AUTOSAR XML (schema 00046)
package /ComponentTypes
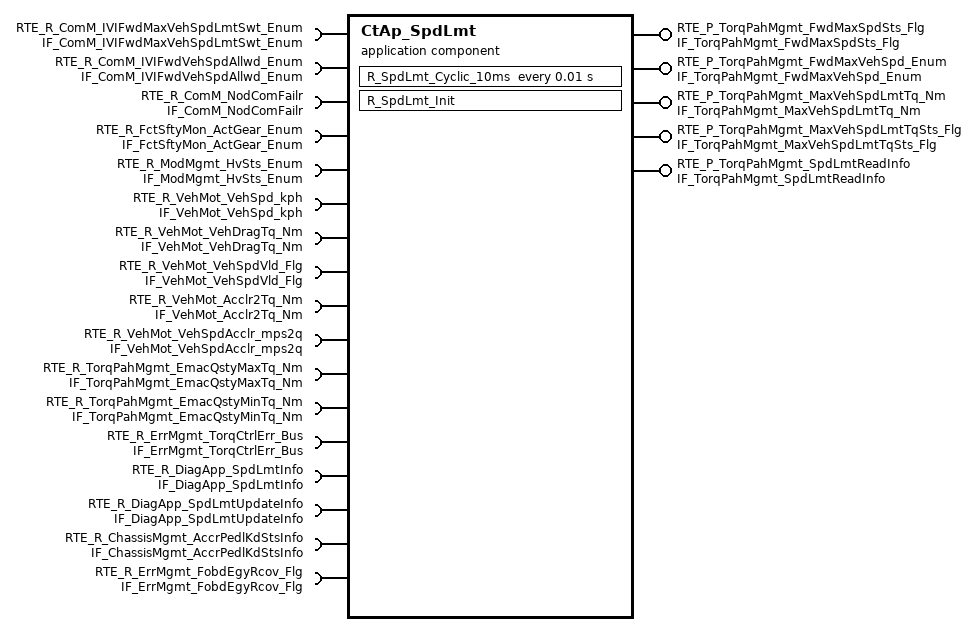
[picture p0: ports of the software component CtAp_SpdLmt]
  application sw component type CtAp_SpdLmt
    10 x require port:
      RTE_R_ComM_IVIFwdMaxVehSpdLmtSwt_Enum: nonqueued-receiver-com-spec{data-element=tec_ComM_IVIFwdMaxVehSpdLmtSwt_Enum, filter=data-filter-type=ALWAYS, init-value=0}, required-interface=IF_ComM_IVIFwdMaxVehSpdLmtSwt_Enum
      RTE_R_ComM_IVIFwdVehSpdAllwd_Enum: nonqueued-receiver-com-spec{data-element=tec_ComM_IVIFwdVehSpdAllwd_Enum, filter=data-filter-type=ALWAYS, init-value=0}, required-interface=IF_ComM_IVIFwdVehSpdAllwd_Enum
      RTE_R_ComM_NodComFailr: required-interface=IF_ComM_NodComFailr
        required-com-specs:
          data-element=tec_ComM_SGWNodComFailr_Flg, filter=data-filter-type=ALWAYS, init-value=0
          data-element=tec_ComM_CGWNodComFailr_Flg, filter=data-filter-type=ALWAYS, init-value=0
          data-element=tec_ComM_TCUNodComFailr_Flg, filter=data-filter-type=ALWAYS, init-value=0
          data-element=tec_ComM_BCMNodComFailr_Flg, filter=data-filter-type=ALWAYS, init-value=0
          data-element=tec_ComM_PRNDNodComFailr_Flg, filter=data-filter-type=ALWAYS, init-value=0
          data-element=tec_ComM_IVINodComFailr_Flg, filter=data-filter-type=ALWAYS, init-value=0
          data-element=tec_ComM_DCDCNodComFailr_Flg, filter=data-filter-type=ALWAYS, init-value=0
          data-element=tec_ComM_OBCNodComFailr_Flg, filter=data-filter-type=ALWAYS, init-value=0
          data-element=tec_ComM_CHIBSNodComFailr_Flg, filter=data-filter-type=ALWAYS, init-value=0
          data-element=tec_ComM_MCUNodComFailr_Flg, filter=data-filter-type=ALWAYS, init-value=0
          data-element=tec_ComM_EVCOMNodComFailr_Flg, filter=data-filter-type=ALWAYS, init-value=0
          data-element=tec_ComM_EPTIBSNodComFailr_Flg, filter=data-filter-type=ALWAYS, init-value=0
          data-element=tec_ComM_DCMNodComFailr_Flg, filter=data-filter-type=ALWAYS, init-value=0
          data-element=tec_ComM_BMSNodComFailr_Flg, filter=data-filter-type=ALWAYS, init-value=0
          data-element=tec_ComM_ACUNodComFailr_Flg, filter=data-filter-type=ALWAYS, init-value=0
          data-element=tec_ComM_APTCNodComFailr_Flg, filter=data-filter-type=ALWAYS, init-value=0
          data-element=tec_ComM_ADCUNodComFailr_Flg, filter=data-filter-type=ALWAYS, init-value=0
          data-element=tec_ComM_DCMRRNodComFailr_Flg, filter=data-filter-type=ALWAYS, init-value=0
          data-element=tec_ComM_DCMRLNodComFailr_Flg, filter=data-filter-type=ALWAYS, init-value=0
          data-element=tec_ComM_DCMFRNodComFailr_Flg, filter=data-filter-type=ALWAYS, init-value=0
          data-element=tec_ComM_DCMFLNodComFailr_Flg, filter=data-filter-type=ALWAYS, init-value=0
          data-element=tec_ComM_SGWCHNodComFailr_Flg, init-value=0
      RTE_R_FctSftyMon_ActGear_Enum: nonqueued-receiver-com-spec{data-element=tec_FctSftyMon_ActGear_Enum, filter=data-filter-type=ALWAYS, init-value=0}, required-interface=IF_FctSftyMon_ActGear_Enum
      RTE_R_ModMgmt_HvSts_Enum: nonqueued-receiver-com-spec{data-element=tec_ModMgmt_HvSts_Enum, filter=data-filter-type=ALWAYS, init-value=0}, required-interface=IF_ModMgmt_HvSts_Enum
      RTE_R_VehMot_VehSpd_kph: nonqueued-receiver-com-spec{data-element=tec_VehMot_VehSpd_kph, filter=data-filter-type=ALWAYS, init-value=0}, required-interface=IF_VehMot_VehSpd_kph
      RTE_R_VehMot_VehDragTq_Nm: nonqueued-receiver-com-spec{data-element=tec_VehMot_VehDragTq_Nm, filter=data-filter-type=ALWAYS, init-value=0}, required-interface=IF_VehMot_VehDragTq_Nm
      RTE_R_VehMot_VehSpdVld_Flg: nonqueued-receiver-com-spec{data-element=tec_VehMot_VehSpdVld_Flg, filter=data-filter-type=ALWAYS, init-value=0}, required-interface=IF_VehMot_VehSpdVld_Flg
      RTE_R_VehMot_Acclr2Tq_Nm: nonqueued-receiver-com-spec{data-element=tec_VehMot_Acclr2Tq_Nm, filter=data-filter-type=ALWAYS, init-value=0}, required-interface=IF_VehMot_Acclr2Tq_Nm
      RTE_R_VehMot_VehSpdAcclr_mps2q: nonqueued-receiver-com-spec{data-element=tec_VehMot_VehSpdAcclr_mps2q, filter=data-filter-type=ALWAYS, init-value=0}, required-interface=IF_VehMot_VehSpdAcclr_mps2q
    4 x provide port:
      RTE_P_TorqPahMgmt_FwdMaxSpdSts_Flg: nonqueued-sender-com-spec{data-element=tec_TorqPahMgmt_FwdMaxSpdSts_Flg, init-value=0}, provided-interface=IF_TorqPahMgmt_FwdMaxSpdSts_Flg
      RTE_P_TorqPahMgmt_FwdMaxVehSpd_Enum: nonqueued-sender-com-spec{data-element=tec_TorqPahMgmt_FwdMaxVehSpd_Enum, init-value=0}, provided-interface=IF_TorqPahMgmt_FwdMaxVehSpd_Enum
      RTE_P_TorqPahMgmt_MaxVehSpdLmtTq_Nm: nonqueued-sender-com-spec{data-element=tec_TorqPahMgmt_MaxVehSpdLmtTq_Nm, init-value=0}, provided-interface=IF_TorqPahMgmt_MaxVehSpdLmtTq_Nm
      RTE_P_TorqPahMgmt_MaxVehSpdLmtTqSts_Flg: nonqueued-sender-com-spec{data-element=tec_TorqPahMgmt_MaxVehSpdLmtTqSts_Flg, init-value=0}, provided-interface=IF_TorqPahMgmt_MaxVehSpdLmtTqSts_Flg
    4 x require port:
      RTE_R_TorqPahMgmt_EmacQstyMaxTq_Nm: nonqueued-receiver-com-spec{data-element=tec_TorqPahMgmt_EmacQstyMaxTq_Nm, filter=data-filter-type=ALWAYS, init-value=0}, required-interface=IF_TorqPahMgmt_EmacQstyMaxTq_Nm
      RTE_R_TorqPahMgmt_EmacQstyMinTq_Nm: nonqueued-receiver-com-spec{data-element=tec_TorqPahMgmt_EmacQstyMinTq_Nm, filter=data-filter-type=ALWAYS, init-value=0}, required-interface=IF_TorqPahMgmt_EmacQstyMinTq_Nm
      RTE_R_ErrMgmt_TorqCtrlErr_Bus: nonqueued-receiver-com-spec{data-element=tec_ErrMgmt_TorqCtrlErr_Bus, filter=data-filter-type=ALWAYS, init-value=fields=[ErrMgmt_DlyGrdtZeroTq_Flg:0, ErrMgmt_GrdtZeroTq_Flg:0, ErrMgmt_ImdtZeroTq_Flg:0, ErrMgmt_VehSpdLim_kph:0, ErrMgmt_VehSpdLimEna_Flg:0]}, required-interface=IF_ErrMgmt_TorqCtrlErr_Bus
      RTE_R_DiagApp_SpdLmtInfo: nonqueued-receiver-com-spec{data-element=tec_DiagApp_SpdLmtInfo, filter=data-filter-type=ALWAYS, init-value=0}, required-interface=IF_DiagApp_SpdLmtInfo
    provide port RTE_P_TorqPahMgmt_SpdLmtReadInfo: nonqueued-sender-com-spec{data-element=tec_TorqPahMgmt_SpdLmtReadInfo, init-value=0}, provided-interface=IF_TorqPahMgmt_SpdLmtReadInfo
    require port RTE_R_DiagApp_SpdLmtUpdateInfo: nonqueued-receiver-com-spec{data-element=tec_DiagApp_SpdLmtUpdateInfo, filter=data-filter-type=ALWAYS, init-value=0}, required-interface=IF_DiagApp_SpdLmtUpdateInfo
    require port RTE_R_ChassisMgmt_AccrPedlKdStsInfo: nonqueued-receiver-com-spec{data-element=tec_ChassisMgmt_AccrPedlKdStsInfo, filter=data-filter-type=ALWAYS, init-value=0}, required-interface=IF_ChassisMgmt_AccrPedlKdStsInfo
    require port RTE_R_ErrMgmt_FobdEgyRcov_Flg: nonqueued-receiver-com-spec{data-element=tec_ErrMgmt_FobdEgyRcov_Flg, filter=data-filter-type=ALWAYS, init-value=0}, required-interface=IF_ErrMgmt_FobdEgyRcov_Flg
    behavior CtAp_SpdLmt_InternalBehavior
      timing event TMT_R_SpdLmt_Cyclic_10ms: start-on-event=R_SpdLmt_Cyclic_10ms, period=0.01
      init event CtAp_SpdLmt_InitEvent: start-on-event=R_SpdLmt_Init
      runnable R_SpdLmt_Cyclic_10ms
        data-receive-point-by-arguments:
          16 x access:
            REC_RTE_R_ComM_IVIFwdMaxVehSpdLmtSwt_Enum_tec_ComM_IVIFwdMaxVehSpdLmtSwt_Enum: accessed-variable=RTE_R_ComM_IVIFwdMaxVehSpdLmtSwt_Enum.tec_ComM_IVIFwdMaxVehSpdLmtSwt_Enum
            REC_RTE_R_ComM_IVIFwdVehSpdAllwd_Enum_tec_ComM_IVIFwdVehSpdAllwd_Enum: accessed-variable=RTE_R_ComM_IVIFwdVehSpdAllwd_Enum.tec_ComM_IVIFwdVehSpdAllwd_Enum
            REC_RTE_R_ComM_NodComFailr_tec_ComM_IVINodComFailr_Flg: accessed-variable=RTE_R_ComM_NodComFailr.tec_ComM_IVINodComFailr_Flg
            REC_RTE_R_ErrMgmt_TorqCtrlErr_Bus_tec_ErrMgmt_TorqCtrlErr_Bus: accessed-variable=RTE_R_ErrMgmt_TorqCtrlErr_Bus.tec_ErrMgmt_TorqCtrlErr_Bus
            REC_RTE_R_FctSftyMon_ActGear_Enum_tec_FctSftyMon_ActGear_Enum: accessed-variable=RTE_R_FctSftyMon_ActGear_Enum.tec_FctSftyMon_ActGear_Enum
            REC_RTE_R_ModMgmt_HvSts_Enum_tec_ModMgmt_HvSts_Enum: accessed-variable=RTE_R_ModMgmt_HvSts_Enum.tec_ModMgmt_HvSts_Enum
            REC_RTE_R_TorqPahMgmt_EmacQstyMaxTq_Nm_tec_TorqPahMgmt_EmacQstyMaxTq_Nm: accessed-variable=RTE_R_TorqPahMgmt_EmacQstyMaxTq_Nm.tec_TorqPahMgmt_EmacQstyMaxTq_Nm
            REC_RTE_R_TorqPahMgmt_EmacQstyMinTq_Nm_tec_TorqPahMgmt_EmacQstyMinTq_Nm: accessed-variable=RTE_R_TorqPahMgmt_EmacQstyMinTq_Nm.tec_TorqPahMgmt_EmacQstyMinTq_Nm
            REC_RTE_R_VehMot_Acclr2Tq_Nm_tec_VehMot_Acclr2Tq_Nm: accessed-variable=RTE_R_VehMot_Acclr2Tq_Nm.tec_VehMot_Acclr2Tq_Nm
            REC_RTE_R_VehMot_VehDragTq_Nm_tec_VehMot_VehDragTq_Nm: accessed-variable=RTE_R_VehMot_VehDragTq_Nm.tec_VehMot_VehDragTq_Nm
            REC_RTE_R_VehMot_VehSpdAcclr_mps2q_tec_VehMot_VehSpdAcclr_mps2q: accessed-variable=RTE_R_VehMot_VehSpdAcclr_mps2q.tec_VehMot_VehSpdAcclr_mps2q
            REC_RTE_R_VehMot_VehSpdVld_Flg_tec_VehMot_VehSpdVld_Flg: accessed-variable=RTE_R_VehMot_VehSpdVld_Flg.tec_VehMot_VehSpdVld_Flg
            REC_RTE_R_VehMot_VehSpd_kph_tec_VehMot_VehSpd_kph: accessed-variable=RTE_R_VehMot_VehSpd_kph.tec_VehMot_VehSpd_kph
            REC_RTE_R_DiagApp_SpdLmtInfo_tec_DiagApp_SpdLmtInfo: accessed-variable=RTE_R_DiagApp_SpdLmtInfo.tec_DiagApp_SpdLmtInfo
            REC_RTE_R_DiagApp_SpdLmtUpdateInfo_tec_DiagApp_SpdLmtUpdateInfo: accessed-variable=RTE_R_DiagApp_SpdLmtUpdateInfo.tec_DiagApp_SpdLmtUpdateInfo
            REC_RTE_R_ChassisMgmt_AccrPedlKdStsInfo_tec_ChassisMgmt_AccrPedlKdStsInfo: accessed-variable=RTE_R_ChassisMgmt_AccrPedlKdStsInfo.tec_ChassisMgmt_AccrPedlKdStsInfo
        data-send-points:
          5 x access:
            SEND_RTE_P_TorqPahMgmt_FwdMaxSpdSts_Flg_tec_TorqPahMgmt_FwdMaxSpdSts_Flg: accessed-variable=RTE_P_TorqPahMgmt_FwdMaxSpdSts_Flg.tec_TorqPahMgmt_FwdMaxSpdSts_Flg
            SEND_RTE_P_TorqPahMgmt_FwdMaxVehSpd_Enum_tec_TorqPahMgmt_FwdMaxVehSpd_Enum: accessed-variable=RTE_P_TorqPahMgmt_FwdMaxVehSpd_Enum.tec_TorqPahMgmt_FwdMaxVehSpd_Enum
            SEND_RTE_P_TorqPahMgmt_MaxVehSpdLmtTqSts_Flg_tec_TorqPahMgmt_MaxVehSpdLmtTqSts_Flg: accessed-variable=RTE_P_TorqPahMgmt_MaxVehSpdLmtTqSts_Flg.tec_TorqPahMgmt_MaxVehSpdLmtTqSts_Flg
            SEND_RTE_P_TorqPahMgmt_MaxVehSpdLmtTq_Nm_tec_TorqPahMgmt_MaxVehSpdLmtTq_Nm: accessed-variable=RTE_P_TorqPahMgmt_MaxVehSpdLmtTq_Nm.tec_TorqPahMgmt_MaxVehSpdLmtTq_Nm
            SEND_RTE_P_TorqPahMgmt_SpdLmtReadInfo_tec_TorqPahMgmt_SpdLmtReadInfo: accessed-variable=RTE_P_TorqPahMgmt_SpdLmtReadInfo.tec_TorqPahMgmt_SpdLmtReadInfo
      runnable R_SpdLmt_Init
  swc implementation CtAp_SpdLmt_Implementation: behavior=CtAp_SpdLmt_InternalBehavior
